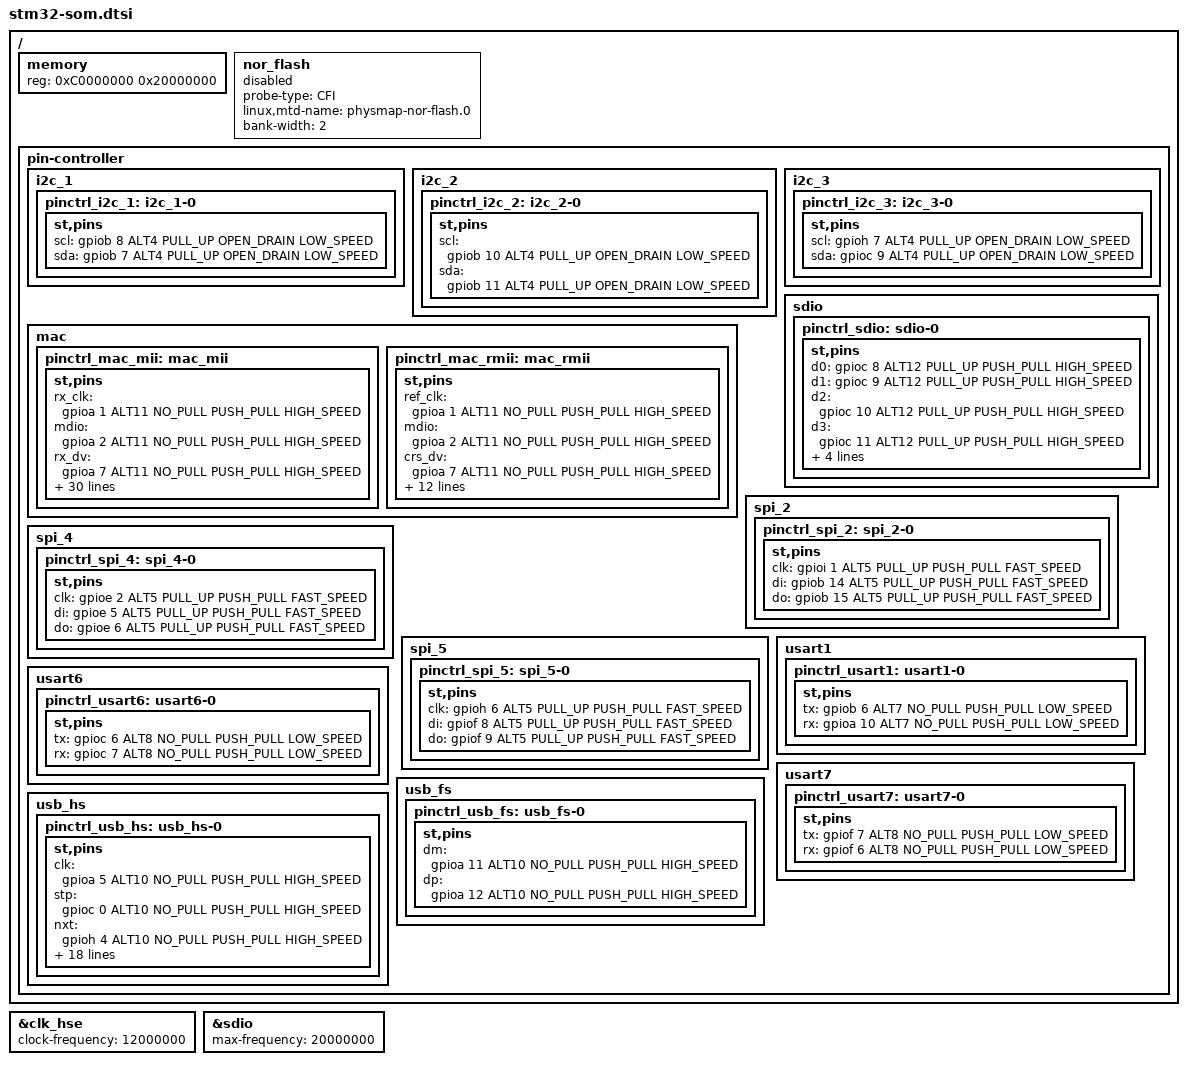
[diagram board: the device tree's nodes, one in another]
/*
 * Copyright 2016
 * Yuri Tikhonov, Emcraft Systems, <yur@emcraft.com>
 *
 * STM32-SOM module
 *
 * This program is free software; you can redistribute it and/or modify
 * it under the terms of the GNU General Public License version 2 as
 * publishhed by the Free Software Foundation.
 */

/ {
	memory {
		reg = <0xC0000000 0x20000000>;
	};

	nor_flash {
		probe-type = "CFI";
		linux,mtd-name = "physmap-nor-flash.0";
		bank-width = <2>;
		#address-cells = <1>;
		#size-cells = <1>;
		status = "disabled";
	};

	pin-controller {
		i2c_1 {
			pinctrl_i2c_1: i2c_1-0 {
				st,pins {
					scl = <&gpiob 8 ALT4
						PULL_UP OPEN_DRAIN LOW_SPEED>;
					sda = <&gpiob 7 ALT4
						PULL_UP OPEN_DRAIN LOW_SPEED>;
				};
			};
		};
		i2c_2 {
			pinctrl_i2c_2: i2c_2-0 {
				st,pins {
					scl = <&gpiob 10 ALT4
						PULL_UP OPEN_DRAIN LOW_SPEED>;
					sda = <&gpiob 11 ALT4
						PULL_UP OPEN_DRAIN LOW_SPEED>;
				};
			};
		};
		i2c_3 {
			pinctrl_i2c_3: i2c_3-0 {
				st,pins {
					scl = <&gpioh 7 ALT4
						PULL_UP OPEN_DRAIN LOW_SPEED>;
					sda = <&gpioc 9 ALT4
						PULL_UP OPEN_DRAIN LOW_SPEED>;
				};
			};
		};

		mac {
			pinctrl_mac_mii: mac_mii {
				st,pins {
					rx_clk = <&gpioa 1 ALT11
						NO_PULL PUSH_PULL HIGH_SPEED>;
					mdio = <&gpioa 2  ALT11
						NO_PULL PUSH_PULL HIGH_SPEED>;
					rx_dv = <&gpioa 7 ALT11
						NO_PULL PUSH_PULL HIGH_SPEED>;
					pps_out = <&gpiob 5 ALT11
						NO_PULL PUSH_PULL HIGH_SPEED>;
					txd3 = <&gpiob 8 ALT11
						NO_PULL PUSH_PULL HIGH_SPEED>;
					mdc = <&gpioc 1 ALT11
						NO_PULL PUSH_PULL HIGH_SPEED>;
					txd2 = <&gpioc 2 ALT11
						NO_PULL PUSH_PULL HIGH_SPEED>;
					tx_clk = <&gpioc 3 ALT11
						NO_PULL PUSH_PULL HIGH_SPEED>;
					rxd0 = <&gpioc 4 ALT11
						NO_PULL PUSH_PULL HIGH_SPEED>;
					rxd1 = <&gpioc 5 ALT11
						NO_PULL PUSH_PULL HIGH_SPEED>;
					tx_en = <&gpiog 11 ALT11
						NO_PULL PUSH_PULL HIGH_SPEED>;
					txd0 = <&gpiog 13 ALT11
						NO_PULL PUSH_PULL HIGH_SPEED>;
					txd1 = <&gpiog 14 ALT11
						NO_PULL PUSH_PULL HIGH_SPEED>;
					crc = <&gpioh 2 ALT11
						NO_PULL PUSH_PULL HIGH_SPEED>;
					col = <&gpioh 3 ALT11
						NO_PULL PUSH_PULL HIGH_SPEED>;
					rxd2 = <&gpioh 6 ALT11
						NO_PULL PUSH_PULL HIGH_SPEED>;
					rxd3 = <&gpioh 7 ALT11
						NO_PULL PUSH_PULL HIGH_SPEED>;
					rx_er = <&gpioi 10 ALT11
						NO_PULL PUSH_PULL HIGH_SPEED>;
				};
			};

			pinctrl_mac_rmii: mac_rmii {
				st,pins {
					ref_clk = <&gpioa 1 ALT11
						NO_PULL PUSH_PULL HIGH_SPEED>;
					mdio = <&gpioa 2 ALT11
						NO_PULL PUSH_PULL HIGH_SPEED>;
					crs_dv = <&gpioa 7 ALT11
						NO_PULL PUSH_PULL HIGH_SPEED>;
					mdc = <&gpioc 1 ALT11
						NO_PULL PUSH_PULL HIGH_SPEED>;
					rxd0 = <&gpioc 4 ALT11
						NO_PULL PUSH_PULL HIGH_SPEED>;
					rxd1 = <&gpioc 5 ALT11
						NO_PULL PUSH_PULL HIGH_SPEED>;
					tx_en = <&gpiog 11 ALT11
						NO_PULL PUSH_PULL HIGH_SPEED>;
					txd0 = <&gpiog 13 ALT11
						NO_PULL PUSH_PULL HIGH_SPEED>;
					txd1 = <&gpiog 14 ALT11
						NO_PULL PUSH_PULL HIGH_SPEED>;
				};
			};
		};

		sdio {
			pinctrl_sdio: sdio-0 {
				st,pins {
					d0 = <&gpioc 8 ALT12
						PULL_UP PUSH_PULL HIGH_SPEED>;
					d1 = <&gpioc 9 ALT12
						PULL_UP PUSH_PULL HIGH_SPEED>;
					d2 = <&gpioc 10 ALT12
						PULL_UP PUSH_PULL HIGH_SPEED>;
					d3 = <&gpioc 11 ALT12
						PULL_UP PUSH_PULL HIGH_SPEED>;
					ck = <&gpioc 12 ALT12
						PULL_UP PUSH_PULL HIGH_SPEED>;
					cmd = <&gpiod 2 ALT12
						PULL_UP PUSH_PULL HIGH_SPEED>;
				};
			};
		};

		spi_2 {
			pinctrl_spi_2: spi_2-0 {
				st,pins {
					clk = <&gpioi 1 ALT5
						PULL_UP PUSH_PULL FAST_SPEED>;
					di = <&gpiob 14 ALT5
						PULL_UP PUSH_PULL FAST_SPEED>;
					do = <&gpiob 15 ALT5
						PULL_UP PUSH_PULL FAST_SPEED>;
				};
			};
		};
		spi_4 {
			pinctrl_spi_4: spi_4-0 {
				st,pins {
					clk = <&gpioe 2 ALT5
						PULL_UP PUSH_PULL FAST_SPEED>;
					di = <&gpioe 5 ALT5
						PULL_UP PUSH_PULL FAST_SPEED>;
					do = <&gpioe 6 ALT5
						PULL_UP PUSH_PULL FAST_SPEED>;
				};
			};
		};
		spi_5 {
			pinctrl_spi_5: spi_5-0 {
				st,pins {
					clk = <&gpioh 6 ALT5
						PULL_UP PUSH_PULL FAST_SPEED>;
					di = <&gpiof 8 ALT5
						PULL_UP PUSH_PULL FAST_SPEED>;
					do = <&gpiof 9 ALT5
						PULL_UP PUSH_PULL FAST_SPEED>;
				};
			};
		};

		usart1 {
			pinctrl_usart1: usart1-0 {
				st,pins {
					tx = <&gpiob 6 ALT7
						NO_PULL PUSH_PULL LOW_SPEED>;
					rx = <&gpioa 10 ALT7
						NO_PULL PUSH_PULL LOW_SPEED>;
				};
			};
		};
		usart6 {
			pinctrl_usart6: usart6-0 {
				st,pins {
					tx = <&gpioc 6 ALT8
						NO_PULL PUSH_PULL LOW_SPEED>;
					rx = <&gpioc 7 ALT8
						NO_PULL PUSH_PULL LOW_SPEED>;
				};
			};
		};
		usart7 {
			pinctrl_usart7: usart7-0 {
				st,pins {
					tx = <&gpiof 7 ALT8
						NO_PULL PUSH_PULL LOW_SPEED>;
					rx = <&gpiof 6 ALT8
						NO_PULL PUSH_PULL LOW_SPEED>;
				};
			};
		};

		usb_fs {
			pinctrl_usb_fs: usb_fs-0 {
				st,pins {
					dm = <&gpioa 11 ALT10
						NO_PULL PUSH_PULL HIGH_SPEED>;
					dp = <&gpioa 12 ALT10
						NO_PULL PUSH_PULL HIGH_SPEED>;
				};
			};
		};
		usb_hs {
			pinctrl_usb_hs: usb_hs-0 {
				st,pins {
					clk = <&gpioa 5 ALT10
						NO_PULL PUSH_PULL HIGH_SPEED>;
					stp = <&gpioc 0 ALT10
						NO_PULL PUSH_PULL HIGH_SPEED>;
					nxt = <&gpioh 4 ALT10
						NO_PULL PUSH_PULL HIGH_SPEED>;
					dir = <&gpioi 11 ALT10
						NO_PULL PUSH_PULL HIGH_SPEED>;

					data0 = <&gpioa 3 ALT10
						NO_PULL PUSH_PULL HIGH_SPEED>;
					data1 = <&gpiob 0 ALT10
						NO_PULL PUSH_PULL HIGH_SPEED>;
					data2 = <&gpiob 1 ALT10
						NO_PULL PUSH_PULL HIGH_SPEED>;
					data3 = <&gpiob 10 ALT10
						NO_PULL PUSH_PULL HIGH_SPEED>;
					data4 = <&gpiob 11 ALT10
						NO_PULL PUSH_PULL HIGH_SPEED>;
					data5 = <&gpiob 12 ALT10
						NO_PULL PUSH_PULL HIGH_SPEED>;
					data6 = <&gpiob 13 ALT10
						NO_PULL PUSH_PULL HIGH_SPEED>;
					data7 = <&gpiob 5 ALT10
						NO_PULL PUSH_PULL HIGH_SPEED>;
				};
			};
		};
	};
};

/*
 * External oscillator used on SOM
 */
&clk_hse {
	clock-frequency = <12000000>;
};


/*
 * SD/MMC interface
 */
&sdio {
      /* Reduce clocks, to avoid MMC errors */
	max-frequency = <20000000>;
};
